# STMP3770 register map
Vendor: Freescale Semiconductor (NXP); Series: STMP37xx; File version: 1.0
CPU: other r0p0, little endian, no MPU, no FPU, 2 interrupt priority bits
Registers are 32-bit, read-write, reset 0x0 unless marked. A register's access mark holds for its fields unless they carry their own. Offsets are from the block's base; [hi:lo] are bit positions.

## SPDIF — S/PDIF 数字音频发送接口
Base 0x80054000
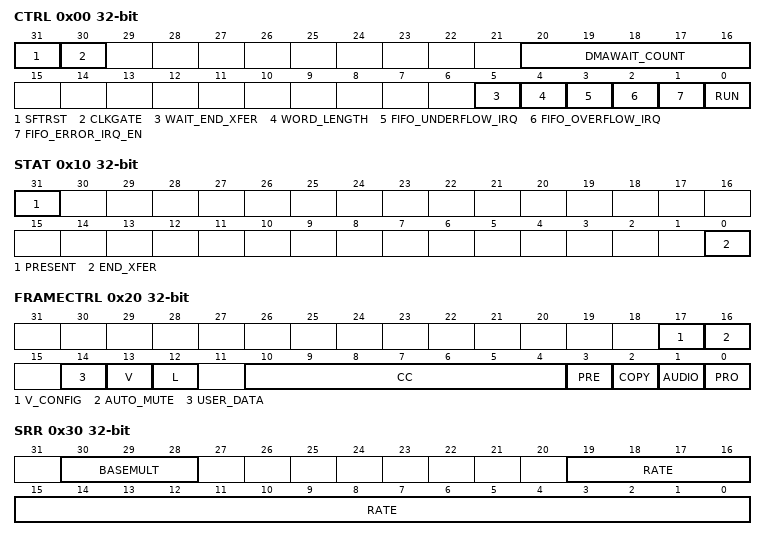
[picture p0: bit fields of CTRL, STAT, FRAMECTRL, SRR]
0x00 CTRL — SPDIF Control Register
  [31] SFTRST — Soft reset. Setting to 1 forces reset to entire block and gates clocks off. Must be cleared to 0 for normal operation. Reset: 0x1.
  [30] CLKGATE — Clock gate. Set to 1 to gate off clocks to block. Must coordinate with HW_CLKCTRL_SPDIF.CLKGATE. Clear to 0 for normal operation.
  [20:16] DMAWAIT_COUNT — DMA Request Delay Count (0-31 APBX clock cycles). Throttles bandwidth consumed by SPDIF block. Can be loaded by DMA. Reset: 0x00.
  [5] WAIT_END_XFER — When set, SPDIF transmitter waits until internal FIFO is empty before halting on RUN deassertion. Use with HW_SPDIF_STAT_END_XFER. Reset: 0x1.
  [4] WORD_LENGTH — 0 = 32-bit mode (24 MSBs of DATA transmitted), 1 = 16-bit mode (8 zeros appended to LSBs). SPDIF frame always transmits only 24 bits. Reset: 0x0.
  [3] FIFO_UNDERFLOW_IRQ — Set by hardware on FIFO underflow during SPDIF transmission. Reset by writing 1 to SCT clear address space. Reset: 0x0.
  [2] FIFO_OVERFLOW_IRQ — Set by hardware on FIFO overflow during SPDIF transmission. Reset by writing 1 to SCT clear address space. Reset: 0x0.
  [1] FIFO_ERROR_IRQ_EN — Enable SPDIF interrupt request on FIFO overflow or underflow status conditions. Reset: 0x0.
  [0] RUN — Set to 1 to start SPDIF conversion. Actual conversion begins when FIFO is filled (4 or 8 words depending on sample format). Reset: 0x0.
0x10 STAT — SPDIF Status Register
  [31] PRESENT — Set to 1 in products where SPDIF is present. Read-only. Reset: 0x1.
  [0] END_XFER — Indicates SPDIF module has completed transfer of all data including internal FIFOs. Use with HW_SPDIF_CTRL.WAIT_END_XFER. Reset: 0x0.
0x20 FRAMECTRL — SPDIF Frame Control Register
  [17] V_CONFIG — SPDIF behavior on invalid frames: 0 = Do NOT tag as invalid, 1 = Tag frame as invalid. Reset: 0x1.
  [16] AUTO_MUTE — Auto-Mute stream on stream-suspend detect. Reset: 0x0.
  [14] USER_DATA — User Data bit. Transmitted during each sub-frame. Consult IEC-60958 for additional details. Reset: 0x0.
  [13] V — Validity bit: 0 = Sub-frame valid (correctly transmitted/received), 1 = Sub-frame invalid. Reset: 0x0.
  [12] L — Generation Level bit. Defined by IEC standard or as appropriate. Reset: 0x0.
  [10:4] CC — Category Code (7 bits). Defined by IEC standard or as appropriate. Reset: 0x0.
  [3] PRE — Pre-Emphasis: 0 = No Pre-Emphasis, 1 = Pre-Emphasis is 50/15 usec. Reset: 0x0.
  [2] COPY — Copyright: 0 = Copyright NOT asserted, 1 = Copyright asserted. Reset: 0x0.
  [1] AUDIO — Audio type: 0 = PCM data, 1 = Non-PCM data. Reset: 0x0.
  [0] PRO — Channel usage: 0 = Consumer use, 1 = Professional use. Reset: 0x0.
0x30 SRR — SPDIF Sample Rate Register
  [30:28] BASEMULT — Base-Rate Multiplier: 1 = Single-Rate (48 kHz), 2 = Double-Rate (96 kHz). Reset: 0x1.
  [19:0] RATE — Sample-Rate Conversion Factor. Valid entries: 0x07D00 (32k), 0x0AC44 (44.1k), 0x0BB80 (48k). Reset: 0x00000.
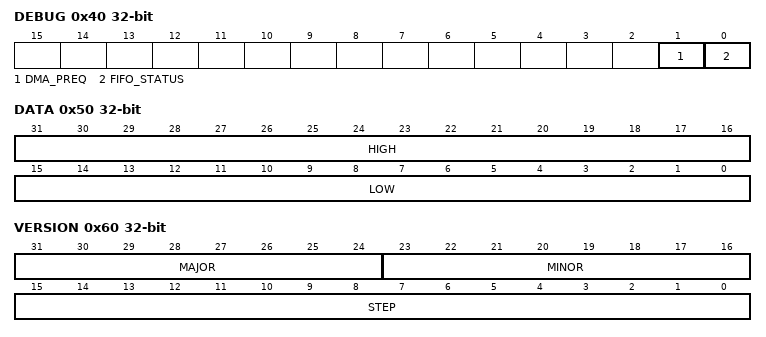
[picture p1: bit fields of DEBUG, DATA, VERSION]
0x40 DEBUG ro — SPDIF Debug Register
  [1] DMA_PREQ — DMA Request Status. Reflects current DMA request signal state. Polled by software for PIO mode data movement. Reset: 0x0.
  [0] FIFO_STATUS — Set when FIFO has empty space, reflecting a DMA request being generated. Reset: 0x1.
0x50 DATA — SPDIF Write Data Register
  [31:16] HIGH — 16-bit mode: entire right channel sample. 32-bit mode: 16 MSBs of the 32-bit sample (left or right). Reset: 0x0000.
  [15:0] LOW — 16-bit mode: entire left channel sample. 32-bit mode: 16 LSBs of the 32-bit sample (left or right). Reset: 0x0000.
0x60 VERSION ro — SPDIF Version Register
  [31:24] MAJOR — Fixed read-only value reflecting the MAJOR field of the RTL version. Reset: 0x01.
  [23:16] MINOR — Fixed read-only value reflecting the MINOR field of the RTL version. Reset: 0x01.
  [15:0] STEP — Fixed read-only value reflecting the stepping of the RTL version. Reset: 0x0000.
